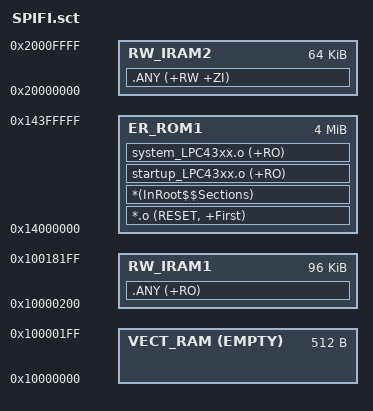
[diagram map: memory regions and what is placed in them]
; *************************************************************
; *** Scatter-Loading Description File generated by uVision ***
; *************************************************************

LR_ROM1 0x14000000 0x00400000  {    ; load region size_region
  ER_ROM1 0x14000000 0x00400000  {  ; load address = execution address
   *.o (RESET, +First)
   *(InRoot$$Sections)
    startup_LPC43xx.o (+RO)
    system_LPC43xx.o (+RO)
  }
  RW_IRAM2 0x20000000 0x00010000  {  ; RW data
   .ANY (+RW +ZI)
  }
  VECT_RAM 0x10000000 EMPTY 0x00000200 {
  }
  RW_IRAM1 0x10000200 0x00018000  {
   .ANY (+RO)
  }
}
